# CMS32L051 register map
Vendor: CMS; Series: CMS32L051; File version: 1.2
CPU: CM0+ r0p1, little endian, no MPU, no FPU, VTOR, 2 interrupt priority bits
Registers are 8-bit, read-write, reset 0x0 unless marked. A register's access mark holds for its fields unless they carry their own. Offsets are from the block's base; [hi:lo] are bit positions; {n}, {i} and the like mark numbered series.

## RST — Reset Function
Base 0x40020420
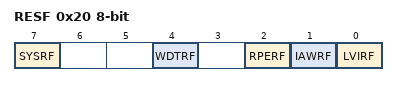
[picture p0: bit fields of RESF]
0x20 RESF ro — Reset flag register
  [all] fields
    0=NONE (Internal reset request is not generated, or the RESF register is cleared.); 1=DONE (Internal reset request is generated.)
  [7] SYSRF read-clears — Internal reset request by system reset request(AIRCR.SYSRESETREQ)
  [4] WDTRF read-clears — Internal reset request by watchdog timer(WDT)
  [2] RPERF read-clears — Internal reset request by RAM parity
  [1] IAWRF read-clears — Internal reset request by illegal-memory access
  [0] LVIRF read-clears — Internal reset request by voltage detector

## LVD — Voltage detector
Base 0x40020440
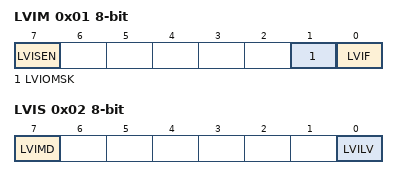
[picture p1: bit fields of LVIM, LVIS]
0x01 LVIM — Voltage detection register
  [7] LVISEN ro — Enable rewritting LVIS register
    0=Disable (Disabling of rewriting the LVIS register); 1=Enable (Enabling of rewriting the LVIS register)
  [1] LVIOMSK ro — Mask status flag of LVD output
    0=Invalid (Mask of LVD output is invalid); 1=Valid (Mask of LVD output is valid)
  [0] LVIF ro — Voltage detection flag
    0=GE (Supply voltage (VDD) greater or equal to detection voltage (VLVD), or when LVD is off); 1=LT (Supply voltage (VDD) less than detection voltage (VLVD))
0x02 LVIS — Voltage detection level register
  [7] LVIMD — Operation mode of voltage detection
    0=IRQ (interrupt mode); 1=reset mode
  [0] LVILV — LVD detection level
    0=High-voltage detection level (VLVDH); 1=Low (Low-voltage detection level (VLVDL or VLVD))

## EPWM — Enhance PWM controller
Base 0x40044400
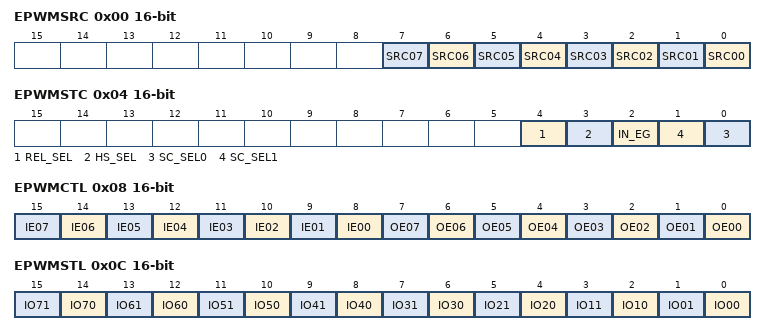
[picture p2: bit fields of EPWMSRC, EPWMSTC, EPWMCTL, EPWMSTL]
0x00 EPWMSRC 16-bit — Input source select register
  [n] SRC0{n} (n=0..7) — Selsect the source clock of EPWM0{n}
0x04 EPWMSTC 16-bit — EPWMO0n cutoff control register
  [4] REL_SEL — Cutoff release timing select register
  [3] HS_SEL — Output forced cutoff release mode selection
  [2] IN_EG — Output forced cutoff source edge/output forced cutoff release edge selection
  [n] SC_SEL{n} (n=0..1) — Cutoff source selection
0x08 EPWMCTL 16-bit — EPWMO0n output control register
  [n+8] IE0{n} (n=0..7) — EPWM0{n} output inverted enable register
  [n] OE0{n} (n=0..7) — EPWM0{n} output enable register
0x0C EPWMSTL 16-bit — EPWMO0n cutoff output level register
  [n+14] IO7{n} (n=0..1) — EPWM07 output enable register
  [n+12] IO6{n} (n=0..1) — EPWM06 output enable register
  [n+10] IO5{n} (n=0..1) — EPWM05 output enable register
  [n+8] IO4{n} (n=0..1) — EPWM04 output enable register
  [n+6] IO3{n} (n=0..1) — EPWM03 output enable register
  [n+4] IO2{n} (n=0..1) — EPWM02 output enable register
  [n+2] IO1{n} (n=0..1) — EPWM01 output enable register
  [n] IO0{n} (n=0..1) — EPWM00 output enable register
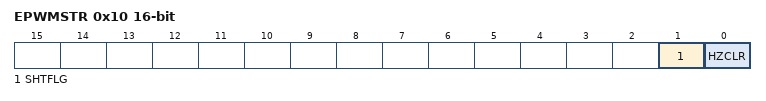
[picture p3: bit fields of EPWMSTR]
0x10 EPWMSTR 16-bit — Status register
  [1] SHTFLG — cutoff status register
  [0] HZCLR — software release cutoff register

## RTC — Real-Time clock
Base 0x40044F00
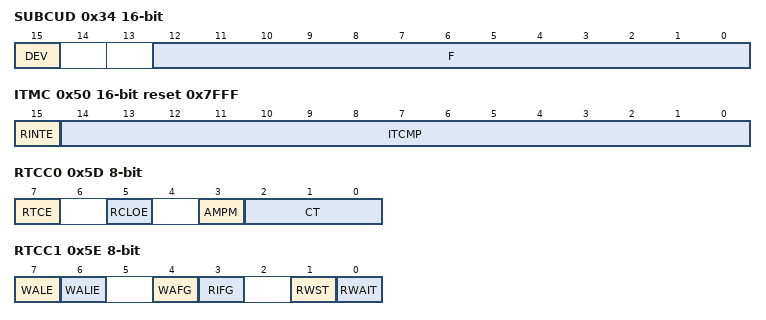
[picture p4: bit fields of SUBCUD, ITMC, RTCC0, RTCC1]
0x34 SUBCUD 16-bit — Watch error correction register
  [15] DEV — watch error correction timing
  [12:0] F — watch error correction value
0x50 ITMC 16-bit reset 0x7FFF — 15-bit interval timer control register
  [15] RINTE — 15-bit interval timer operation control
  [14:0] ITCMP — 15-bit interval timer compare value
0x52 SEC (reset mask 0x7F) — Second count register
0x53 MIN (reset mask 0x7F) — Minute count register
0x54 HOUR reset 0x12 (reset mask 0x3F) — Hour count register
0x55 WEEK (reset mask 0x7) — Week count register
0x56 DAY reset 0x1 (reset mask 0x3F) — Day count register
0x57 MONTH reset 0x1 (reset mask 0x1F) — Month count register
0x58 YEAR — Year count register
0x5A ALARMWM (reset mask 0x7F) — Alarm minute register
0x5B ALARMWH reset 0x12 (reset mask 0x3F) — Alarm hour register
0x5C ALARMWW (reset mask 0x3F) — Alarm week register
0x5D RTCC0 — Real-time clock control register 0
  [7] RTCE — Real-time clock operation control
  [5] RCLOE — RTC1HZ pin output enable
  [3] AMPM — Selection of 12-/24-hour system
  [2:0] CT — Constant-period interrupt (INTRTC) selection
0x5E RTCC1 — Real-time clock control register 1
  [7] WALE — Alarm operation control
  [6] WALIE — Control of alarm interrupt (INTRTC) function operation
  [4] WAFG — Alarm detection status flag
  [3] RIFG — Constant-period interrupt status flag
  [1] RWST — Wait status flag of real-time clock
  [0] RWAIT — Wait control of real-time clock
